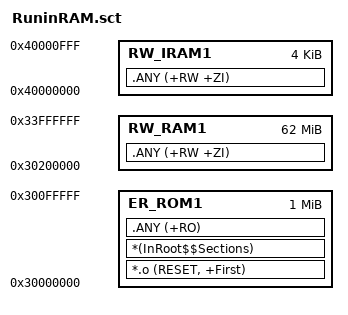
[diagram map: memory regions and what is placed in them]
; *************************************************************
; *** Scatter-Loading Description File generated by uVision ***
; *************************************************************
; Run in RAM

LR_ROM1 0x30000000         {    ; load region
  ER_ROM1 0x30000000 0x00100000  {  ; load address = execution address
   *.o (RESET, +First)
   *(InRoot$$Sections)
   .ANY (+RO)
  }
  RW_RAM1 0x30200000 0x3E00000  {  ; RW data
   .ANY (+RW +ZI)
  }
   RW_IRAM1 0x40000000 0x00001000  {
   .ANY (+RW +ZI)
  }
}

